AUTOSAR XML (schema 4-0-3)
standard types defined: Boolean, UInt16, UInt32, UInt8
package /AUTOSAR_Platform/DataConstrs
  range DC_Boolean: raw 0..1
  range DC_UInt16: raw 0..65535
  range DC_UInt8: raw 0..255
package /PATAC/MSM/ComponentTypes
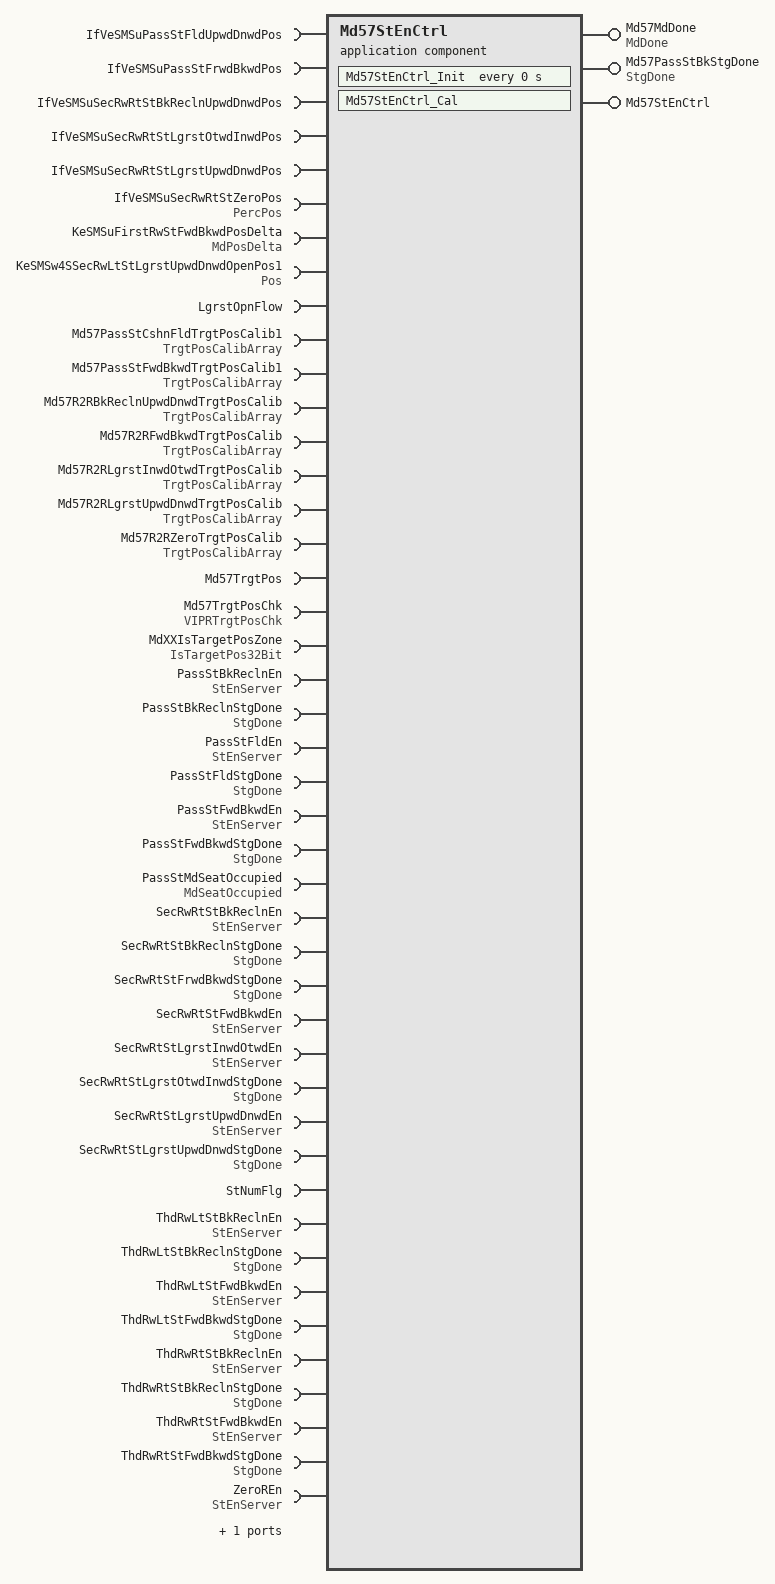
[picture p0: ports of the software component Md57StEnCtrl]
  application sw component type Md57StEnCtrl
    provide port Md57MdDone: nonqueued-sender-com-spec{data-element=MdDone/Val, init-value=0}, provided-interface=MdDone
    provide port Md57PassStBkStgDone: nonqueued-sender-com-spec{data-element=StgDone/Val, init-value=0}, provided-interface=StgDone
    provide port Md57StEnCtrl: server-com-spec{operation=Md57StEnCtrl/Cal, queue-length=1}, provided-interface=Md57StEnCtrl
    45 x require port:
      IfVeSMSuPassStFldUpwdDnwdPos: nonqueued-receiver-com-spec{data-element=IfVeSMSuPassStFldUpwdDnwdPos/Val, filter=data-filter-type=ALWAYS, init-value=0}, required-interface=IfVeSMSuPassStFldUpwdDnwdPos
      IfVeSMSuPassStFrwdBkwdPos: nonqueued-receiver-com-spec{data-element=IfVeSMSuPassStFrwdBkwdPos/Val, filter=data-filter-type=ALWAYS, init-value=0}, required-interface=IfVeSMSuPassStFrwdBkwdPos
      IfVeSMSuSecRwRtStBkReclnUpwdDnwdPos: nonqueued-receiver-com-spec{data-element=IfVeSMSuSecRwRtStBkReclnUpwdDnwdPos/Val, filter=data-filter-type=ALWAYS, init-value=0}, required-interface=IfVeSMSuSecRwRtStBkReclnUpwdDnwdPos
      IfVeSMSuSecRwRtStLgrstOtwdInwdPos: nonqueued-receiver-com-spec{data-element=IfVeSMSuSecRwRtStLgrstOtwdInwdPos/Val, filter=data-filter-type=ALWAYS, init-value=0}, required-interface=IfVeSMSuSecRwRtStLgrstOtwdInwdPos
      IfVeSMSuSecRwRtStLgrstUpwdDnwdPos: nonqueued-receiver-com-spec{data-element=IfVeSMSuSecRwRtStLgrstUpwdDnwdPos/Val, filter=data-filter-type=ALWAYS, init-value=0}, required-interface=IfVeSMSuSecRwRtStLgrstUpwdDnwdPos
      IfVeSMSuSecRwRtStZeroPos: nonqueued-receiver-com-spec{data-element=PercPos/Val, filter=data-filter-type=ALWAYS, init-value=0}, required-interface=PercPos
      KeSMSuFirstRwStFwdBkwdPosDelta: parameter-require-com-spec{init-value=150, parameter=MdPosDelta/Val}, required-interface=MdPosDelta
      KeSMSw4SSecRwLtStLgrstUpwdDnwdOpenPos1: parameter-require-com-spec{init-value=0, parameter=Pos/Val}, required-interface=Pos
      LgrstOpnFlow: client-com-spec=LgrstOpnFlow/Cal, required-interface=LgrstOpnFlow
      Md57PassStCshnFldTrgtPosCalib1: nonqueued-receiver-com-spec{data-element=TrgtPosArray, filter=data-filter-type=ALWAYS, init-value=[0, 0, 0]}, required-interface=TrgtPosCalibArray
      Md57PassStFwdBkwdTrgtPosCalib1: nonqueued-receiver-com-spec{data-element=TrgtPosArray, filter=data-filter-type=ALWAYS, init-value=[0, 0, 0]}, required-interface=TrgtPosCalibArray
      Md57R2RBkReclnUpwdDnwdTrgtPosCalib: nonqueued-receiver-com-spec{data-element=TrgtPosArray, filter=data-filter-type=ALWAYS, init-value=[4095, 4095, 4095]}, required-interface=TrgtPosCalibArray
      Md57R2RFwdBkwdTrgtPosCalib: nonqueued-receiver-com-spec{data-element=TrgtPosArray, filter=data-filter-type=ALWAYS, init-value=[4095, 4095, 4095]}, required-interface=TrgtPosCalibArray
      Md57R2RLgrstInwdOtwdTrgtPosCalib: nonqueued-receiver-com-spec{data-element=TrgtPosArray, filter=data-filter-type=ALWAYS, init-value=[4095, 4095, 4095]}, required-interface=TrgtPosCalibArray
      Md57R2RLgrstUpwdDnwdTrgtPosCalib: nonqueued-receiver-com-spec{data-element=TrgtPosArray, filter=data-filter-type=ALWAYS, init-value=[4095, 4095, 4095]}, required-interface=TrgtPosCalibArray
      Md57R2RZeroTrgtPosCalib: nonqueued-receiver-com-spec{data-element=TrgtPosArray, filter=data-filter-type=ALWAYS, init-value=[4095, 4095, 4095]}, required-interface=TrgtPosCalibArray
      Md57TrgtPos: required-com-specs=[Md57TrgtPos/Get, Md57TrgtPos/Set], required-interface=Md57TrgtPos
      Md57TrgtPosChk: client-com-spec=VIPRTrgtPosChk/Cal, required-interface=VIPRTrgtPosChk
      MdXXIsTargetPosZone: nonqueued-receiver-com-spec{data-element=IsTargetPos32Bit/Val, filter=data-filter-type=ALWAYS, init-value=0}, required-interface=IsTargetPos32Bit
      PassStBkReclnEn: required-com-specs=[Clear, StEnServer/Get, StEnServer/Set], required-interface=StEnServer
      PassStBkReclnStgDone: nonqueued-receiver-com-spec{data-element=StgDone/Val, filter=data-filter-type=ALWAYS, init-value=0}, required-interface=StgDone
      PassStFldEn: required-com-specs=[Clear, StEnServer/Get, StEnServer/Set], required-interface=StEnServer
      PassStFldStgDone: nonqueued-receiver-com-spec{data-element=StgDone/Val, filter=data-filter-type=ALWAYS, init-value=0}, required-interface=StgDone
      PassStFwdBkwdEn: required-com-specs=[Clear, StEnServer/Get, StEnServer/Set], required-interface=StEnServer
      PassStFwdBkwdStgDone: nonqueued-receiver-com-spec{data-element=StgDone/Val, filter=data-filter-type=ALWAYS, init-value=0}, required-interface=StgDone
      PassStMdSeatOccupied: nonqueued-receiver-com-spec{data-element=MdSeatOccupied/Val, filter=data-filter-type=ALWAYS, init-value=0}, required-interface=MdSeatOccupied
      SecRwRtStBkReclnEn: required-com-specs=[Clear, StEnServer/Get, StEnServer/Set], required-interface=StEnServer
      SecRwRtStBkReclnStgDone: nonqueued-receiver-com-spec{data-element=StgDone/Val, filter=data-filter-type=ALWAYS, init-value=0}, required-interface=StgDone
      SecRwRtStFrwdBkwdStgDone: nonqueued-receiver-com-spec{data-element=StgDone/Val, filter=data-filter-type=ALWAYS, init-value=0}, required-interface=StgDone
      SecRwRtStFwdBkwdEn: required-com-specs=[Clear, StEnServer/Get, StEnServer/Set], required-interface=StEnServer
      SecRwRtStLgrstInwdOtwdEn: required-com-specs=[Clear, StEnServer/Get, StEnServer/Set], required-interface=StEnServer
      SecRwRtStLgrstOtwdInwdStgDone: nonqueued-receiver-com-spec{data-element=StgDone/Val, filter=data-filter-type=ALWAYS, init-value=0}, required-interface=StgDone
      SecRwRtStLgrstUpwdDnwdEn: required-com-specs=[Clear, StEnServer/Get, StEnServer/Set], required-interface=StEnServer
      SecRwRtStLgrstUpwdDnwdStgDone: nonqueued-receiver-com-spec{data-element=StgDone/Val, filter=data-filter-type=ALWAYS, init-value=0}, required-interface=StgDone
      StNumFlg: required-interface=StNumFlg
        required-com-specs:
          data-element=Is4s, filter=data-filter-type=ALWAYS, init-value=0
          data-element=Is6s, filter=data-filter-type=ALWAYS, init-value=0
          data-element=Is6s7s, filter=data-filter-type=ALWAYS, init-value=0
          data-element=Is7s, filter=data-filter-type=ALWAYS, init-value=0
      ThdRwLtStBkReclnEn: required-com-specs=[Clear, StEnServer/Get, StEnServer/Set], required-interface=StEnServer
      ThdRwLtStBkReclnStgDone: nonqueued-receiver-com-spec{data-element=StgDone/Val, filter=data-filter-type=ALWAYS, init-value=0}, required-interface=StgDone
      ThdRwLtStFwdBkwdEn: required-com-specs=[Clear, StEnServer/Get, StEnServer/Set], required-interface=StEnServer
      ThdRwLtStFwdBkwdStgDone: nonqueued-receiver-com-spec{data-element=StgDone/Val, filter=data-filter-type=ALWAYS, init-value=0}, required-interface=StgDone
      ThdRwRtStBkReclnEn: required-com-specs=[Clear, StEnServer/Get, StEnServer/Set], required-interface=StEnServer
      ThdRwRtStBkReclnStgDone: nonqueued-receiver-com-spec{data-element=StgDone/Val, filter=data-filter-type=ALWAYS, init-value=0}, required-interface=StgDone
      ThdRwRtStFwdBkwdEn: required-com-specs=[Clear, StEnServer/Get, StEnServer/Set], required-interface=StEnServer
      ThdRwRtStFwdBkwdStgDone: nonqueued-receiver-com-spec{data-element=StgDone/Val, filter=data-filter-type=ALWAYS, init-value=0}, required-interface=StgDone
      ZeroREn: required-com-specs=[Clear, StEnServer/Get, StEnServer/Set], required-interface=StEnServer
      ZeroRStgDone: nonqueued-receiver-com-spec{data-element=StgDone/Val, filter=data-filter-type=ALWAYS, init-value=0}, required-interface=StgDone
    behavior Md57StEnCtrl_InternalBehavior
      operation invoked event OIT_Md57StEnCtrl_Cal_Md57StEnCtrl_Cal: start-on-event=Md57StEnCtrl_Cal, operation=Md57StEnCtrl.Cal
      timing event Md57StEnCtrl_InitEvent: start-on-event=Md57StEnCtrl_Init, period=0
      runnable Md57StEnCtrl_Cal
        data-receive-point-by-arguments:
          31 x access:
            REC_IfVeSMSuPassStFldUpwdDnwdPos_Val: accessed-variable=IfVeSMSuPassStFldUpwdDnwdPos.Val
            REC_IfVeSMSuPassStFrwdBkwdPos_Val: accessed-variable=IfVeSMSuPassStFrwdBkwdPos.Val
            REC_IfVeSMSuSecRwRtStBkReclnUpwdDnwdPos_Val: accessed-variable=IfVeSMSuSecRwRtStBkReclnUpwdDnwdPos.Val
            REC_IfVeSMSuSecRwRtStLgrstOtwdInwdPos_Val: accessed-variable=IfVeSMSuSecRwRtStLgrstOtwdInwdPos.Val
            REC_IfVeSMSuSecRwRtStLgrstUpwdDnwdPos_Val: accessed-variable=IfVeSMSuSecRwRtStLgrstUpwdDnwdPos.Val
            REC_IfVeSMSuSecRwRtStZeroPos_Val: accessed-variable=IfVeSMSuSecRwRtStZeroPos.Val
            REC_Md57PassStCshnFldTrgtPosCalib1_TrgtPosArray: accessed-variable=Md57PassStCshnFldTrgtPosCalib1.TrgtPosArray
            REC_Md57PassStFwdBkwdTrgtPosCalib1_TrgtPosArray: accessed-variable=Md57PassStFwdBkwdTrgtPosCalib1.TrgtPosArray
            REC_Md57R2RBkReclnUpwdDnwdTrgtPosCalib_TrgtPosArray: accessed-variable=Md57R2RBkReclnUpwdDnwdTrgtPosCalib.TrgtPosArray
            REC_Md57R2RFwdBkwdTrgtPosCalib_TrgtPosArray: accessed-variable=Md57R2RFwdBkwdTrgtPosCalib.TrgtPosArray
            REC_Md57R2RLgrstInwdOtwdTrgtPosCalib_TrgtPosArray: accessed-variable=Md57R2RLgrstInwdOtwdTrgtPosCalib.TrgtPosArray
            REC_Md57R2RLgrstUpwdDnwdTrgtPosCalib_TrgtPosArray: accessed-variable=Md57R2RLgrstUpwdDnwdTrgtPosCalib.TrgtPosArray
            REC_Md57R2RZeroTrgtPosCalib_TrgtPosArray: accessed-variable=Md57R2RZeroTrgtPosCalib.TrgtPosArray
            REC_MdXXIsTargetPosZone_Val: accessed-variable=MdXXIsTargetPosZone.Val
            REC_PassStBkReclnStgDone_Val: accessed-variable=PassStBkReclnStgDone.Val
            REC_PassStFldStgDone_Val: accessed-variable=PassStFldStgDone.Val
            REC_PassStFwdBkwdStgDone_Val: accessed-variable=PassStFwdBkwdStgDone.Val
            REC_PassStMdSeatOccupied_Val: accessed-variable=PassStMdSeatOccupied.Val
            REC_SecRwRtStBkReclnStgDone_Val: accessed-variable=SecRwRtStBkReclnStgDone.Val
            REC_SecRwRtStFrwdBkwdStgDone_Val: accessed-variable=SecRwRtStFrwdBkwdStgDone.Val
            REC_SecRwRtStLgrstOtwdInwdStgDone_Val: accessed-variable=SecRwRtStLgrstOtwdInwdStgDone.Val
            REC_SecRwRtStLgrstUpwdDnwdStgDone_Val: accessed-variable=SecRwRtStLgrstUpwdDnwdStgDone.Val
            REC_StNumFlg_Is4s: accessed-variable=StNumFlg.Is4s
            REC_StNumFlg_Is6s: accessed-variable=StNumFlg.Is6s
            REC_StNumFlg_Is6s7s: accessed-variable=StNumFlg.Is6s7s
            REC_StNumFlg_Is7s: accessed-variable=StNumFlg.Is7s
            REC_ThdRwLtStBkReclnStgDone_Val: accessed-variable=ThdRwLtStBkReclnStgDone.Val
            REC_ThdRwLtStFwdBkwdStgDone_Val: accessed-variable=ThdRwLtStFwdBkwdStgDone.Val
            REC_ThdRwRtStBkReclnStgDone_Val: accessed-variable=ThdRwRtStBkReclnStgDone.Val
            REC_ThdRwRtStFwdBkwdStgDone_Val: accessed-variable=ThdRwRtStFwdBkwdStgDone.Val
            REC_ZeroRStgDone_Val: accessed-variable=ZeroRStgDone.Val
        data-send-points:
          access SEND_Md57MdDone_Val: accessed-variable=Md57MdDone.Val
          access SEND_Md57PassStBkStgDone_Val: accessed-variable=Md57PassStBkStgDone.Val
        parameter access PA_KeSMSuFirstRwStFwdBkwdPosDelta_Val: accessed-parameter=KeSMSuFirstRwStFwdBkwdPosDelta.Val
        parameter access PA_KeSMSw4SSecRwLtStLgrstUpwdDnwdOpenPos1_Val: accessed-parameter=KeSMSw4SSecRwLtStLgrstUpwdDnwdOpenPos1.Val
        27 x sync call, all with timeout=0:
          SC_LgrstOpnFlow_Cal: operation=LgrstOpnFlow.Cal
          SC_Md57TrgtPos_Get: operation=Md57TrgtPos.Get
          SC_Md57TrgtPosChk_Cal: operation=Md57TrgtPosChk.Cal
          SC_PassStBkReclnEn_Clear: operation=PassStBkReclnEn.Clear
          SC_PassStBkReclnEn_Set: operation=PassStBkReclnEn.Set
          SC_PassStFldEn_Clear: operation=PassStFldEn.Clear
          SC_PassStFldEn_Set: operation=PassStFldEn.Set
          SC_PassStFwdBkwdEn_Clear: operation=PassStFwdBkwdEn.Clear
          SC_PassStFwdBkwdEn_Set: operation=PassStFwdBkwdEn.Set
          SC_SecRwRtStBkReclnEn_Clear: operation=SecRwRtStBkReclnEn.Clear
          SC_SecRwRtStBkReclnEn_Set: operation=SecRwRtStBkReclnEn.Set
          SC_SecRwRtStFwdBkwdEn_Clear: operation=SecRwRtStFwdBkwdEn.Clear
          SC_SecRwRtStFwdBkwdEn_Set: operation=SecRwRtStFwdBkwdEn.Set
          SC_SecRwRtStLgrstInwdOtwdEn_Clear: operation=SecRwRtStLgrstInwdOtwdEn.Clear
          SC_SecRwRtStLgrstInwdOtwdEn_Set: operation=SecRwRtStLgrstInwdOtwdEn.Set
          SC_SecRwRtStLgrstUpwdDnwdEn_Clear: operation=SecRwRtStLgrstUpwdDnwdEn.Clear
          SC_SecRwRtStLgrstUpwdDnwdEn_Set: operation=SecRwRtStLgrstUpwdDnwdEn.Set
          SC_ThdRwLtStBkReclnEn_Clear: operation=ThdRwLtStBkReclnEn.Clear
          SC_ThdRwLtStBkReclnEn_Set: operation=ThdRwLtStBkReclnEn.Set
          SC_ThdRwLtStFwdBkwdEn_Clear: operation=ThdRwLtStFwdBkwdEn.Clear
          SC_ThdRwLtStFwdBkwdEn_Set: operation=ThdRwLtStFwdBkwdEn.Set
          SC_ThdRwRtStBkReclnEn_Clear: operation=ThdRwRtStBkReclnEn.Clear
          SC_ThdRwRtStBkReclnEn_Set: operation=ThdRwRtStBkReclnEn.Set
          SC_ThdRwRtStFwdBkwdEn_Clear: operation=ThdRwRtStFwdBkwdEn.Clear
          SC_ThdRwRtStFwdBkwdEn_Set: operation=ThdRwRtStFwdBkwdEn.Set
          SC_ZeroREn_Clear: operation=ZeroREn.Clear
          SC_ZeroREn_Set: operation=ZeroREn.Set
      runnable Md57StEnCtrl_Init
        parameter access PA_KeSMSuFirstRwStFwdBkwdPosDelta_Val: accessed-parameter=KeSMSuFirstRwStFwdBkwdPosDelta.Val
        parameter access PA_KeSMSw4SSecRwLtStLgrstUpwdDnwdOpenPos1_Val: accessed-parameter=KeSMSw4SSecRwLtStLgrstUpwdDnwdOpenPos1.Val
  swc implementation Md57StEnCtrl_Implementation: behavior=Md57StEnCtrl_InternalBehavior
    code-descriptors:
      code Default: artifact-descriptors=autosar-engineering-object={short-label=Default, category=SWSRC}
package /PATAC/MSM/Intervene/PortInterfaces
  client server interface VIPRTrgtPosChk  # PosAvl：1模式可用 PosAvl：0模式不可用
    operation Cal
      arg PosAvl: type=DataTypes/UInt8, direction=OUT, server-argument-impl-policy=USE-ARGUMENT-TYPE
package /PATAC/MSM/ModeAdjust/CalPortInterface
  parameter interface MdPosDelta
    parameter data prototype Val: sw-calibration-access=READ-WRITE, type=UInt16
  parameter interface Pos
    parameter data prototype Val: sw-calibration-access=READ-WRITE, type=UInt16
package /PATAC/MSM/ModeAdjust/DataType
  impl type TrgtPosCalibArray: category=ARRAY, sw-calibration-access=READ-ONLY, type-emitter=RTE  # 0:pos 1:max 2:min
    element Element: array-size=3, array-size-semantics=FIXED-SIZE, implementation-data-type=UInt16, invalid-value=0
package /PATAC/MSM/ModeAdjust/PortInterface
  4 x client server interface:
    LgrstOpnFlow
      operation Cal
        9 x arg, all with server-argument-impl-policy=USE-ARGUMENT-TYPE:
          LgrstUpwdDnwdPos: type=UInt16, direction=IN
          LgrstUpwdDnwdOpenPos1: type=UInt16, direction=IN
          LgrstUpwdStgDone: type=Implementation/Boolean, direction=IN
          FtrstStgDone: type=Implementation/Boolean, direction=IN
          LgrstInwdStgDone: type=Implementation/Boolean, direction=IN
          Failflg: type=Implementation/Boolean, direction=OUT
          LgrstInwdOtwdEn: type=Implementation/Boolean, direction=OUT
          LgrstUpwdDnwdEn: type=Implementation/Boolean, direction=OUT
          FtrstEn: type=Implementation/Boolean, direction=OUT
    Md57StEnCtrl
      operation Cal
        arg FirstTrig: type=DataTypes/Boolean, direction=IN, server-argument-impl-policy=USE-ARGUMENT-TYPE
    Md57TrgtPos
      operation Get
        5 x arg, all with type=UInt16, direction=OUT, server-argument-impl-policy=USE-ARGUMENT-TYPE:
          SecRwLtStBkReclnTrgtPos
          SecRwLtStZeroTrgtPos
          SecRwLtStLgrstUpwdDnwdTrgtPos
          SecRwLtStLgrstInwdOtwdTrgtPos
          SecRwLtStFwdBkwdTrgtPos
      operation Set
        5 x arg, all with type=UInt16, direction=IN, server-argument-impl-policy=USE-ARGUMENT-TYPE:
          SecRwLtStBkReclnTrgtPos
          SecRwLtStZeroTrgtPos
          SecRwLtStLgrstUpwdDnwdTrgtPos
          SecRwLtStLgrstInwdOtwdTrgtPos
          SecRwLtStFwdBkwdTrgtPos
    StEnServer
      operation Clear
        arg data: type=Implementation/UInt8, direction=IN, server-argument-impl-policy=USE-ARGUMENT-TYPE
      operation Get
        arg data: type=UInt32, direction=OUT, server-argument-impl-policy=USE-ARGUMENT-TYPE
      operation Set
        arg data: type=Implementation/UInt8, direction=IN, server-argument-impl-policy=USE-ARGUMENT-TYPE
  8 x sender receiver interface:
    IfVeSMSuPassStFldUpwdDnwdPos: invalidation-policy{data-element=IfVeSMSuPassStFldUpwdDnwdPos/Val, handle-invalid=DONT-INVALIDATE}
      data Val: type=UInt16
    IsTargetPos32Bit: invalidation-policy{data-element=IsTargetPos32Bit/Val, handle-invalid=DONT-INVALIDATE}
      data Val: type=UInt32
    MdDone: invalidation-policy{data-element=MdDone/Val, handle-invalid=DONT-INVALIDATE}
      data Val: type=Implementation/UInt8
    MdSeatOccupied: invalidation-policy{data-element=MdSeatOccupied/Val, handle-invalid=DONT-INVALIDATE}
      data Val: type=Implementation/Boolean
    PercPos: invalidation-policy{data-element=PercPos/Val, handle-invalid=DONT-INVALIDATE}
      data Val: type=UInt16
    StgDone: invalidation-policy{data-element=StgDone/Val, handle-invalid=DONT-INVALIDATE}
      data Val: type=Implementation/Boolean
    StNumFlg
      4 x data, all with type=Implementation/Boolean:
        Is4s
        Is6s
        Is6s7s
        Is7s
      invalidation-policys:
        data-element=Is4s, handle-invalid=DONT-INVALIDATE
        data-element=Is6s, handle-invalid=DONT-INVALIDATE
        data-element=Is6s7s, handle-invalid=DONT-INVALIDATE
        data-element=Is7s, handle-invalid=DONT-INVALIDATE
    TrgtPosCalibArray: invalidation-policy{data-element=TrgtPosArray, handle-invalid=DONT-INVALIDATE}
      data TrgtPosArray: type=TrgtPosCalibArray  # 0:Pos 1:Max 2:Min
package /PATAC/MSM/PortInterfaces
  4 x sender receiver interface:
    IfVeSMSuPassStFrwdBkwdPos: invalidation-policy{data-element=IfVeSMSuPassStFrwdBkwdPos/Val, handle-invalid=DONT-INVALIDATE}
      data Val: type=UInt16
    IfVeSMSuSecRwRtStBkReclnUpwdDnwdPos: invalidation-policy{data-element=IfVeSMSuSecRwRtStBkReclnUpwdDnwdPos/Val, handle-invalid=DONT-INVALIDATE}
      data Val: type=UInt16
    IfVeSMSuSecRwRtStLgrstOtwdInwdPos: invalidation-policy{data-element=IfVeSMSuSecRwRtStLgrstOtwdInwdPos/Val, handle-invalid=DONT-INVALIDATE}
      data Val: type=UInt16
    IfVeSMSuSecRwRtStLgrstUpwdDnwdPos: invalidation-policy{data-element=IfVeSMSuSecRwRtStLgrstUpwdDnwdPos/Val, handle-invalid=DONT-INVALIDATE}
      data Val: type=UInt16
